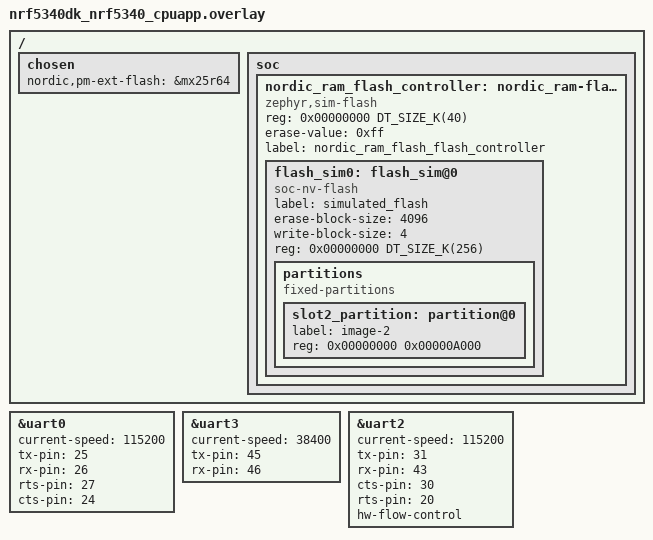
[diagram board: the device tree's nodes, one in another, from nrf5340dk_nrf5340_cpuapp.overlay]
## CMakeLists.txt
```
# SPDX-License-Identifier: Apache-2.0

cmake_minimum_required(VERSION 3.20.0)

list(APPEND ZEPHYR_EXTRA_MODULES ${CMAKE_CURRENT_SOURCE_DIR}/../ubxlib)
find_package(Zephyr REQUIRED HINTS $ENV{ZEPHYR_BASE})
project(cloudlocate_example)

FILE(GLOB app_sources src/*.c)
FILE(GLOB head_sources src/*.h)

target_include_directories(app PRIVATE ${CMAKE_CURRENT_SOURCE_DIR}/src)
target_sources(app PRIVATE ${app_sources})
target_sources(app PRIVATE ${head_sources})
```

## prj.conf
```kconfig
CONFIG_SOC_SERIES_NRF53X=y
CONFIG_SERIAL=y
CONFIG_UART_NRFX=y

CONFIG_CONSOLE_SUBSYS=y
CONFIG_CONSOLE_GETCHAR=y


# docs at https://docs.zephyrproject.org/latest/reference/kconfig/index.html
CONFIG_DEBUG=y
CONFIG_MINIMAL_LIBC=n
# This is the memory used by the porting layer
CONFIG_HEAP_MEM_POOL_SIZE=131072
CONFIG_USERSPACE=y
CONFIG_NET_BUF_USER_DATA_SIZE=4

CONFIG_MINIMAL_LIBC_MALLOC=n

# Enable ubxlib
CONFIG_UBXLIB=y

#CONFIG_UBXLIB_GNSS=y

CONFIG_UART_INTERRUPT_DRIVEN=y

#To get uPortTaskStackMinFree() working
CONFIG_INIT_STACKS=y
CONFIG_THREAD_STACK_INFO=y
CONFIG_THREAD_NAME=y

# To be able to use semaphore from ISR
CONFIG_IRQ_OFFLOAD=y

#Sufficient main stack to pass all tests and leave
#5 kbytes slack for user code
CONFIG_MAIN_STACK_SIZE=7048

# Add the basic Zephyr random number generator.
# IMPORTANT: this is only psuedo-random and is unlikely
# to be  sufficient for your needs, please check/test
# if you are intending to build production code.
CONFIG_TEST_RANDOM_GENERATOR=n
CONFIG_ENTROPY_DEVICE_RANDOM_GENERATOR=n

# Don't hide any potential errors
CONFIG_ASSERT=y

# SEGGER RTT logging instead of UART
CONFIG_LOG=y
CONFIG_LOG_DEFAULT_LEVEL=3
#If Log level 4 is set the log stack size needs to be increased
#CONFIG_LOG_PROCESS_THREAD_STACK_SIZE=8096
CONFIG_USE_SEGGER_RTT=n
CONFIG_RTT_CONSOLE=n
CONFIG_UART_CONSOLE=y
CONFIG_LOG_BACKEND_UART=y
CONFIG_LOG_BACKEND_SHOW_COLOR=y
# End of SEGGER RTT

# Enable debug thread info
CONFIG_OPENOCD_SUPPORT=y
CONFIG_DEBUG_OPTIMIZATIONS=y 
CONFIG_DEBUG_THREAD_INFO=y

# Enable bootloader application
CONFIG_BOOTLOADER_MCUBOOT=y

#Enable shell
CONFIG_SHELL=y
CONFIG_SHELL_STACK_SIZE=4096
CONFIG_SHELL_CMDS=n
CONFIG_KERNEL_SHELL=n
CONFIG_DEVICE_SHELL=n
CONFIG_DEVMEM_SHELL=n
CONFIG_FLASH_SHELL=n
CONFIG_PWM_SHELL=n
CONFIG_CLOCK_CONTROL_NRF_SHELL=n
CONFIG_I2C_SHELL=n
 
```

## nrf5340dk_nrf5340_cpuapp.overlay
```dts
/*
 * Copyright (c) 2021 Nordic Semiconductor ASA
 *
 * SPDX-License-Identifier: LicenseRef-Nordic-5-Clause
 */

/ {
	chosen {
		nordic,pm-ext-flash = &mx25r64;
	};

	soc {
		/* Add a flash controller which has the compatible
		 * 'zephyr,sim-flash'. This will ensure that the flash
		 * simulator can use it. None of the other properties in this
		 * node is used for anything.
		 */
		nordic_ram_flash_controller: nordic_ram-flash-controller@0 {
			compatible = "zephyr,sim-flash";
			reg = <0x00000000 DT_SIZE_K(40)>;
			#address-cells = <1>;
			#size-cells = <1>;
			erase-value = <0xff>;
			label = "nordic_ram_flash_flash_controller";

			/* This node label must match that used in the flash
			 * simulator.
			 */
			flash_sim0: flash_sim@0 {
				status = "okay";
				compatible = "soc-nv-flash";
				label = "simulated_flash";
				erase-block-size = <4096>;
				write-block-size = <4>;
				reg = <0x00000000 DT_SIZE_K(256)>;

				partitions {
					compatible = "fixed-partitions";
					#address-cells = <1>;
					#size-cells = <1>;

					/* This partition must be defined for
					 * MCUboot to find the partition ID
					 * of the primary slot for image 1,
					 * which is stored in this partition.
					 */
					slot2_partition: partition@0 {
						label = "image-2";
						reg = <0x00000000 0x00000A000>;
					};
				};
			};
		};
	};
};


// console uart
&uart0 {
	status = "okay";
	current-speed = <115200>;
	tx-pin = <25>;
	rx-pin = <26>;
	rts-pin = <27>;
	cts-pin = <24>;
};


// MaxM10S uart
&uart3 {
	status = "okay";
	current-speed = <38400>;
	tx-pin = <45>;
	rx-pin = <46>;
};

// Default configuration is set on the NINA-W156 pins, the same UART is also used by SARA-R5
&uart2 {
	status = "okay";
	current-speed = <115200>;
	tx-pin = <31>;  
	rx-pin = <43>;
	cts-pin = <30>;  
	rts-pin = <20>;  
	hw-flow-control;
};
```

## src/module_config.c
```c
/*
 * Copyright 2020 u-blox
 *
 * Licensed under the Apache License, Version 2.0 (the "License");
 * you may not use this file except in compliance with the License.
 * You may obtain a copy of the License at
 *
 *  http://www.apache.org/licenses/LICENSE-2.0
 *
 * Unless required by applicable law or agreed to in writing, software
 * distributed under the License is distributed on an "AS IS" BASIS,
 * WITHOUT WARRANTIES OR CONDITIONS OF ANY KIND, either express or implied.
 * See the License for the specific language governing permissions and
 * limitations under the License.
 */


/** 
 * @file module_config.c
 * @brief Functions for different configurations of all the modules on XPLR-IOT-1 Kit
 */


#include "module_config.h"
#include <zephyr.h>
#include <hal/nrf_gpio.h>
#include <hal/nrf_uarte.h>
#include <drivers/uart.h>

/*!
 * @brief Sara uart configuration 
 */
UARTE_PSEL_Type SARA ={
    SARA_UART_RTS,
    SARA_UART_TX,
    SARA_UART_CTS,
    SARA_UART_RX
};

/*!
 * @brief Nora uart configuration 
 */
UARTE_PSEL_Type NORA ={
    NORA_UART_RTS,
    NORA_UART_TX,
    NORA_UART_CTS,
    NORA_UART_RX
};


/** \fn nina15ResetEnable(void)
 * @brief Enabling reset on Nina-W15
*/
void nina15ResetEnable(void)
{
    // Apply VCC to NINA
    nrf_gpio_cfg_output((uint32_t) NINA_RESET_PIN);
    nrf_gpio_pin_set((uint32_t) NINA_RESET_PIN);
}

/** \fn nina15ResetDisable(void)
 * @brief Disabling reset on Nina-W15
*/
void nina15ResetDisable(void)
{
    // Disable VCC to NINA
    nrf_gpio_cfg_output((uint32_t) NINA_RESET_PIN);
    nrf_gpio_pin_clear((uint32_t) NINA_RESET_PIN);
}

/** \fn void nina15Enable(void)
 * @brief Nina-W15 enabled
*/
void nina15Enable(void)
{
    // Apply VCC to NINA
    nrf_gpio_cfg_output((uint32_t) NINA_EN_PIN);
    nrf_gpio_pin_set((uint32_t) NINA_EN_PIN);
}

/** \fn void nina15Disable(void)
 * @brief Nina-W15 disabled
*/
void nina15Disable(void)
{
    // Disable VCC to NINA
    nrf_gpio_cfg_output((uint32_t) NINA_EN_PIN);
    nrf_gpio_pin_clear((uint32_t) NINA_EN_PIN);
}

/** \fn void ninaNoraCommEnable(void)
 * @brief Enabling communication between Nina-W15 and Nora-B1
*/
void ninaNoraCommEnable(void)
{
    // Select UARTE Comm, UART-BRIDGE comm de-select
    nrf_gpio_cfg_output((uint32_t) NORA_NINA_COMM_EN_PIN);
    nrf_gpio_pin_set((uint32_t) NORA_NINA_COMM_EN_PIN);
}

/** \fn void ninaNoraCommDisable(void)
 * @brief Disabling communication between Nina-W15 and Nora-B1
*/
void ninaNoraCommDisable(void)
{
    nrf_gpio_cfg_output((uint32_t) NORA_NINA_COMM_EN_PIN);
    nrf_gpio_pin_clear((uint32_t) NORA_NINA_COMM_EN_PIN);

}

/** \fn void nina15InitPower(void)
 * @brief Nina-W15 powered ON
*/
void nina15InitPower(void)
{
    nina15Enable();

    // Initialize the NINA module, we will hold it in reset until it is powered toggle reset
    nina15ResetEnable();
    k_sleep(K_MSEC(10));
    nina15ResetDisable();

    // t_Startup time after release of reset UBX-18006647 - R10 (page 23)
    k_sleep(K_MSEC(2600));
}

/** \fn void saraR5InitPower(void)
 * @brief SARA R5 powered ON
*/
void saraR5InitPower(void)
{
    
    nrf_gpio_cfg_output((uint32_t) NORA_EN_SARA_PIN);
    nrf_gpio_cfg_output((uint32_t) SARA_PWR_ON_PIN);
    

    // Power on sequence

    // Apply power to the module and wait a little time
    nrf_gpio_pin_set((uint32_t) NORA_EN_SARA_PIN);
    k_sleep(K_MSEC(500));
    
    //assert POWER_ON pin for a valid time
    nrf_gpio_pin_set((uint32_t) SARA_PWR_ON_PIN);
    k_sleep(K_MSEC(2100));
    //deassert POWER_ON pin
    nrf_gpio_pin_clear((uint32_t) SARA_PWR_ON_PIN);
    
}

/** \fn void saraR5Disable(void)
 * @brief SARA R5 powered OFF
*/
void saraR5Disable(void)
{
    // disable VCC to SaraR5
    nrf_gpio_cfg_output((uint32_t) NORA_EN_SARA_PIN);
    nrf_gpio_pin_clear((uint32_t) NORA_EN_SARA_PIN);
}

/** \fn void max10Enable(void)
 * @brief M10 GNSS receiver enabled
*/
void max10Enable(void)
{
    // Apply VCC to max10
    nrf_gpio_cfg_output((uint32_t) EN_MAX_PIN);
    nrf_gpio_pin_set((uint32_t) EN_MAX_PIN);
}

/** \fn void max10Disable(void)
 * @brief M10 GNSS receiver disabled
*/
void max10Disable(void)
{
    // Apply VCC to
    nrf_gpio_cfg_output((uint32_t) EN_MAX_PIN);
    nrf_gpio_pin_clear((uint32_t) EN_MAX_PIN);
}

/** \fn void max10SafeBootEnable(void)
 * @brief M10 GNSS receiver Safe Boot mode enabled
*/
void max10SafeBootEnable(void)
{
    // Apply VCC to max10
    nrf_gpio_cfg_output((uint32_t) MAX_SAFEBOOT_NOT_PIN);
    nrf_gpio_pin_set((uint32_t) MAX_SAFEBOOT_NOT_PIN);
}

/** \fn void max10SafeBootDisable(void)
 * @brief M10 GNSS receiver safe boot mode disabled
*/
void max10SafeBootDisable(void)
{
    // Apply VCC to
    nrf_gpio_cfg_output((uint32_t) MAX_SAFEBOOT_NOT_PIN);
    nrf_gpio_pin_clear((uint32_t) MAX_SAFEBOOT_NOT_PIN);
}

/** \fn void max10BackupSupplyEnable(void)
 * @brief M10 GNSS receiver backup supply enabled
*/
void max10BackupSupplyEnable(void)
{
    // Apply VCC to max10
    nrf_gpio_cfg_output((uint32_t) MAX_BACKUP_ENABLE_PIN);
    nrf_gpio_pin_set((uint32_t) MAX_BACKUP_ENABLE_PIN);
}

/** \fn void max10BackupSupplyDisable(void)
 * @brief M10 GNSS receiver backup supply disabled
*/
void max10BackupSupplyDisable(void)
{
    // Apply VCC to
    nrf_gpio_cfg_output((uint32_t) MAX_BACKUP_ENABLE_PIN);
    nrf_gpio_pin_clear((uint32_t) MAX_BACKUP_ENABLE_PIN);
}

/** \fn void max10NoraCommEnable(void)
 * @brief Enabling communication between M10 and Nora-B1
*/
void max10NoraCommEnable(void)
{
    // Apply VCC to
    nrf_gpio_cfg_output((uint32_t) MAX_COM_EN_PIN);
    nrf_gpio_pin_set((uint32_t) MAX_COM_EN_PIN);
}

/** \fn void max10NoraCommDisable(void)
 * @brief Disabling communication between M10 and Nora-B1
*/
void max10NoraCommDisable(void)
{
    // Apply VCC to
    nrf_gpio_cfg_output((uint32_t) MAX_COM_EN_PIN);
    nrf_gpio_pin_clear((uint32_t) MAX_COM_EN_PIN);
}


/** \fn void setUartConfig(uartype type)
 * @brief Setting UART configurations
*/
void setUartConfig(uartype type){

    UARTE_PSEL_Type pins;

    if(type == SARAuart){
        pins = SARA;
    }
    else if(type == NORAuart){
        pins = NORA;
    }
    else{
        return;
    }

    nrf_uarte_disable(NRF_UARTE2_S);
    
    // Set up TX and RX pins.
    nrf_gpio_pin_set(pins.TXD);
    nrf_gpio_cfg_output(pins.TXD);
    nrf_gpio_cfg_input(pins.RXD, NRF_GPIO_PIN_NOPULL);
    nrf_uarte_txrx_pins_set(NRF_UARTE2_S, pins.TXD, pins.RXD);

    // Set up CTS and RTS pins.
    nrf_gpio_cfg_input(pins.CTS, NRF_GPIO_PIN_NOPULL);
    nrf_gpio_pin_set(pins.RTS);
    nrf_gpio_cfg_output(pins.RTS);
    nrf_uarte_hwfc_pins_set(NRF_UARTE2_S, pins.RTS, pins.CTS);

    // enable UARTE
    nrf_uarte_enable(NRF_UARTE2_S);
    // kick-start Rx
    nrf_uarte_task_trigger(NRF_UARTE2_S, NRF_UARTE_TASK_STARTRX);

}
```

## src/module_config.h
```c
/*
 * Copyright 2020 u-blox
 *
 * Licensed under the Apache License, Version 2.0 (the "License");
 * you may not use this file except in compliance with the License.
 * You may obtain a copy of the License at
 *
 *  http://www.apache.org/licenses/LICENSE-2.0
 *
 * Unless required by applicable law or agreed to in writing, software
 * distributed under the License is distributed on an "AS IS" BASIS,
 * WITHOUT WARRANTIES OR CONDITIONS OF ANY KIND, either express or implied.
 * See the License for the specific language governing permissions and
 * limitations under the License.
 */
 
 
/** 
 * @file module_config.h
 * @brief Macros definitions and header of the functions for different configurations of all the modules on XPLR-IOT-1 Kit
 */

/* ------------------------------------------------------------------------------
 * COMPILE-TIME MACROS
 * -----------------------------------------------------------------------------*/

#ifndef _MODULE_CONFIG_H_
#define _MODULE_CONFIG_H_

#define NINA_RESET_PIN          41    /* active low */
#define NINA_EN_PIN              8    /* Applies voltage railt to NINA module */
#define NORA_NINA_COMM_EN_PIN   42    /* Uart routes to NORA */


#define SARA_RESET_PIN 21           /* RESET */
#define SARA_PWR_ON_PIN 9           /* Applies POWER_ON Signal */
#define NORA_EN_SARA_PIN 10         /* Applies voltage rail to  module */
//#define SARA_INT_PIN 33             /* INT Pin Signal */

#define SARA_UART_RX    40
#define SARA_UART_TX    36
#define SARA_UART_CTS   38
#define SARA_UART_RTS   19

#define NORA_UART_RX    43
#define NORA_UART_TX    31
#define NORA_UART_CTS   30
#define NORA_UART_RTS   20

#define EN_MAX_PIN              4    /* enables M10 voltage rail */
#define MAX_BACKUP_ENABLE_PIN   37   /* Applies backup voltage rail to  module */
#define MAX_SAFEBOOT_NOT_PIN    44   /* ! during reset puts device in safeboot mode */ 
#define MAX_COM_EN_PIN          47   /* COM goes to NORA */

/*!
 * @brief SARA and NORA Uart
 */
typedef enum{
    SARAuart,
    NORAuart
}uartype;


/* ------------------------------------------------------------------------------
 * CONFIGURATION FUNCTIONS DECLARATIONS
 * -----------------------------------------------------------------------------*/

void nina15ResetEnable(void);

void nina15ResetDisable(void);

void nina15Enable(void);

void nina15Disable(void);

void ninaNoraCommEnable(void);

void ninaNoraCommDisable(void);


void nina15InitPower(void);

void saraR5InitPower(void);

void saraR5Disable(void);

void max10Enable(void);

void max10Disable(void);

void max10SafeBootEnable(void);

void max10SafeBootDisable(void);

void max10BackupSupplyEnable(void);

void max10BackupSupplyDisable(void);

void max10NoraCommEnable(void);

void max10NoraCommDisable(void);

void setUartConfig(uartype type);

	
#endif // _MODULE_CONFIG_H_
```
